# fcr_me17 register map
Registers are read-write, no defined reset value unless marked. A register's access mark holds for its fields unless they carry their own. Offsets are from the block's base; lines under a group give offsets from that group; [hi:lo] are bit positions; {n}, {i} and the like mark numbered series; 'fields as' and 'values as' point back to an identical list; <NAME> marks a mode.

## Memory map
0x40000800 FCR size 0x400 — Function Control Register.

## FCR — Function Control Register.
Base 0x40000800
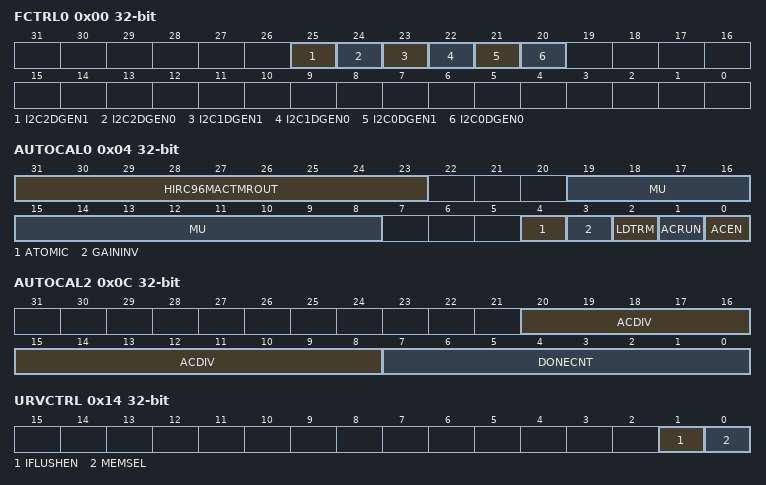
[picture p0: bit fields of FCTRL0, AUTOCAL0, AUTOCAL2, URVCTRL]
0x00 FCTRL0 — Function Control 0.
  [all] fields
    0=dis (Deglitcher disabled.); 1=en (Deglitcher enabled.)
  [25] I2C2DGEN1 — I2C2 SCL Pad Deglitcher enable.
  [24] I2C2DGEN0 — I2C2 SDA Pad Deglitcher enable.
  [23] I2C1DGEN1 — I2C1 SCL Pad Deglitcher enable.
  [22] I2C1DGEN0 — I2C1 SDA Pad Deglitcher enable.
  [21] I2C0DGEN1 — I2C0 SCL Pad Deglitcher enable.
  [20] I2C0DGEN0 — I2C0 SDA Pad Deglitcher enable.
0x04 AUTOCAL0 — Automatic Calibration 0.
  [31:23] HIRC96MACTMROUT — HIRC96M Trim Value.
  [19:8] MU — MU value.
  [4] ATOMIC — Atomic mode.
    0=not (Not Running.); 1=run (Running.)
  [3] GAININV — Invert Gain.
    0=not (Not Running.); 1=run (Running.)
  [2] LDTRM — Load Trim.
  [1] ACRUN — Autocalibration Run.
    0=not (Not Running.); 1=run (Running.)
  [0] ACEN — Auto-calibration Enable.
    0=dis (Disabled.); 1=en (Enabled.)
0x08 AUTOCAL1 — Automatic Calibration 1.
  [8:0] INITTRM — Initial Trim Setting.
0x0C AUTOCAL2 — Automatic Calibration 2
  [20:8] ACDIV — Auto-callibration Div Setting.
  [7:0] DONECNT — Auto-callibration Done Counter Setting.
0x10 URVBOOTADDR — RISC-V Boot Address.
0x14 URVCTRL — RISC-V Control Register.
  [1] IFLUSHEN — URV instruction flush enable.
  [0] MEMSEL — RAM2, RAM3 exclusive ownership.
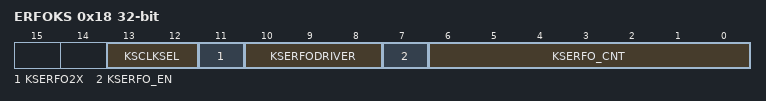
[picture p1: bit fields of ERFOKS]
0x18 ERFOKS — ERFO Kick Start Register.
  [13:12] KSCLKSEL — Kick Start Clock Select for ERFO.
    2=ISO; 3=IPO
  [11] KSERFO2X — Kick Start ERFO 2X Pulse.
  [10:8] KSERFODRIVER — Kick Start ERFO Driver.
  [7] KSERFO_EN — Kick Start ERFO Enable.
  [6:0] KSERFO_CNT — Kick Start ERFO Counter.
0x1C ERFO_INTFL — ERFO Ready Interrupt Flag register.
  [0] rdy — Ready interrupt flag.
0x20 ERFO_INTEN — ERFO Ready Interrupt Enable register.
  [0] rdy — Ready interrupt enable.
